# ing920 register map
Vendor: INGChips; Series: ing920xx; File version: 1.0
CPU: CM3 r2p1, little endian, no MPU, no FPU, 2 interrupt priority bits
Registers are 32-bit, read-write, reset 0x0 unless marked. A register's access mark holds for its fields unless they carry their own. Offsets are from the block's base; [hi:lo] are bit positions; {n}, {i} and the like mark numbered series.

## I2C
Base 0x40013000
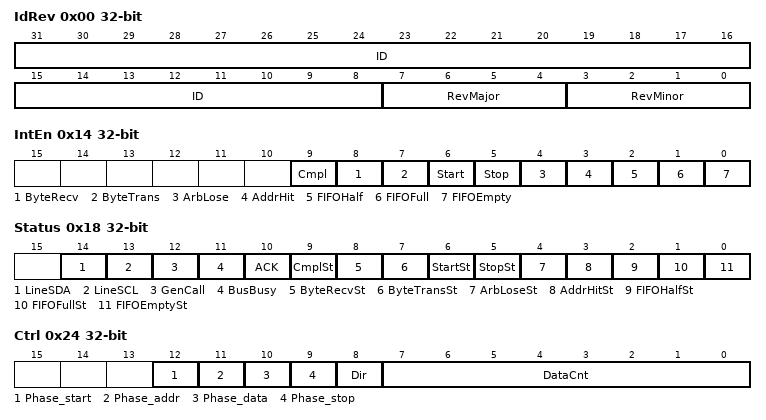
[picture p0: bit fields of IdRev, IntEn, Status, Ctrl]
0x00 IdRev — reg description:
  [31:8] ID — reg description:
  [7:4] RevMajor — reg description:
  [3:0] RevMinor — reg description:
0x10 Cfg — reg description:
  [1:0] FIFOSize
0x14 IntEn — reg description:
  [9] Cmpl — reg description:
  [8] ByteRecv — reg description:
  [7] ByteTrans — reg description:
  [6] Start — reg description:
  [5] Stop — reg description:
  [4] ArbLose — reg description:
  [3] AddrHit — reg description:
  [2] FIFOHalf — reg description:
  [1] FIFOFull — reg description:
  [0] FIFOEmpty — reg description:
0x18 Status — reg description:
  [14] LineSDA — reg description:
  [13] LineSCL — reg description:
  [12] GenCall — reg description:
  [11] BusBusy — reg description:
  [10] ACK — reg description:
  [9] CmplSt — reg description:
  [8] ByteRecvSt — reg description:
  [7] ByteTransSt — reg description:
  [6] StartSt — reg description:
  [5] StopSt — reg description:
  [4] ArbLoseSt — reg description:
  [3] AddrHitSt — reg description:
  [2] FIFOHalfSt — reg description:
  [1] FIFOFullSt — reg description:
  [0] FIFOEmptySt — reg description:
0x1C Addr — reg description:
  [9:0] Addr
0x20 Data — reg description:
  [7:0] Data
0x24 Ctrl — reg description:
  [12] Phase_start — reg description:
  [11] Phase_addr — reg description:
  [10] Phase_data — reg description:
  [9] Phase_stop — reg description:
  [8] Dir — reg description:
  [7:0] DataCnt — reg description:
0x28 Cmd — reg description:
  [2:0] CMD
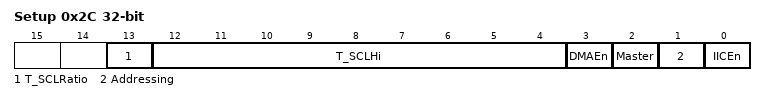
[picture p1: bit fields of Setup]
0x2C Setup — reg description:
  [13] T_SCLRatio — reg description:
  [12:4] T_SCLHi — reg description:
  [3] DMAEn — reg description:
  [2] Master — reg description:
  [1] Addressing — reg description:
  [0] IICEn — reg description:
0x30 TPM — reg description:
  [4:0] TPM

## GPIO0
Base 0x40015000
Same registers: GPIO1 0x40016000
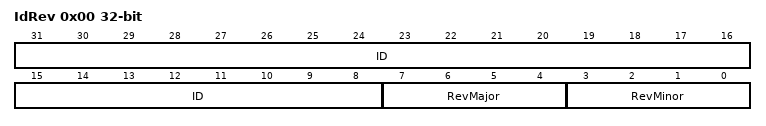
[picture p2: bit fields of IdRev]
0x00 IdRev — reg description:
  [31:8] ID — reg description:
  [7:4] RevMajor — reg description:
  [3:0] RevMinor — reg description:
0x10 Cfg — reg description:
  [5:0] ChannelNum
0x20 DataIn — reg description:
  [20:0] DataIn
0x24 DataOut — reg description:
  [20:0] DataOut
0x28 ChannelDir — reg description:
  [20:0] ChannelDir
0x2C DoutClear — reg description:
  [20:0] DoutClear
0x30 DoutSet — reg description:
  [20:0] DoutSet
0x34 IOIE — reg description:
  [20:0] gpio_ie_reg
0x50 IntrEn — reg description:
  [20:0] IntEn
{0x54+4i} IntrMode{i} (i=0..2) — reg description:
  [2:0] Ch{8i}IntrM
0x64 IntrStatus — reg description:
  [20:0] IntrStatus
0x70 DeBounceEn — reg description:
  [20:0] DeBounceEn
0x74 DeBounceCtrl — reg description:
  [7:0] DBPreScale

## CACHE_CTRL
Base 0x40140000
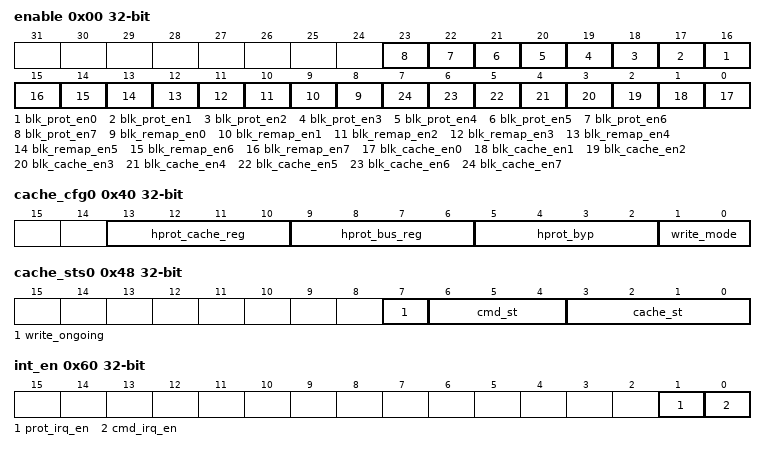
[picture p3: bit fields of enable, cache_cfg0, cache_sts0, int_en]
0x00 enable — reg description:
  [n+16] blk_prot_en{n} (n=0..7) — reg description:
  [n+8] blk_remap_en{n} (n=0..7) — reg description:
  [n] blk_cache_en{n} (n=0..7) — reg description:
{0x0+4i} base_addr{i} (i=1..7) — reg description:
{0x20+4i} remap{i} (i=0..7) — reg description:
0x40 cache_cfg0 — reg description:
  [13:10] hprot_cache_reg — reg description:
  [9:6] hprot_bus_reg — reg description:
  [5:2] hprot_byp — reg description:
  [1:0] write_mode — reg description:
0x44 bus_sts0 — reg description:
  [27:0] prot_detect_addr
0x48 cache_sts0 — reg description:
  [7] write_ongoing — reg description:
  [6:4] cmd_st — reg description:
  [3:0] cache_st — reg description:
0x50 cmd_cfg0 — reg description:
  [27:0] cmd_str_addr
0x54 cmd_cfg1 — reg description:
  [27:0] cmd_end_addr
0x58 cmd_cfg2 — reg description:
  [5:0] cmd_type
0x60 int_en — reg description:
  [1] prot_irq_en — reg description:
  [0] cmd_irq_en — reg description:
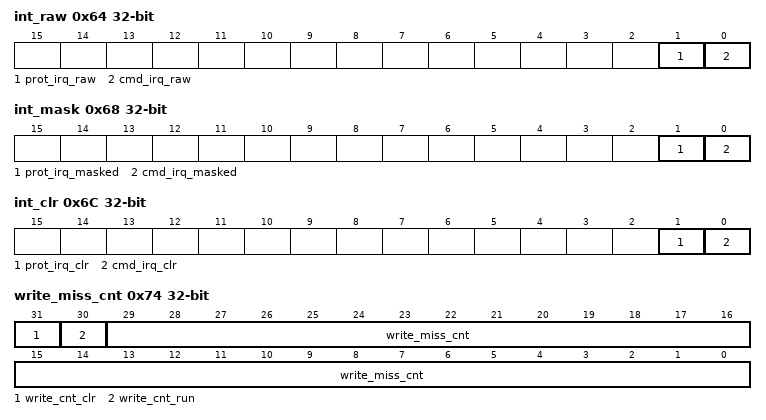
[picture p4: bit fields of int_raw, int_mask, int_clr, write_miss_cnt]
0x64 int_raw — reg description:
  [1] prot_irq_raw — reg description:
  [0] cmd_irq_raw — reg description:
0x68 int_mask — reg description:
  [1] prot_irq_masked — reg description:
  [0] cmd_irq_masked — reg description:
0x6C int_clr — reg description:
  [1] prot_irq_clr — reg description:
  [0] cmd_irq_clr — reg description:
0x70 write_hit_cnt — reg description:
0x74 write_miss_cnt — reg description:
  [31] write_cnt_clr — reg description:
  [30] write_cnt_run — reg description:
  [29:0] write_miss_cnt — reg description:
0x78 read_hit_cnt — reg description:
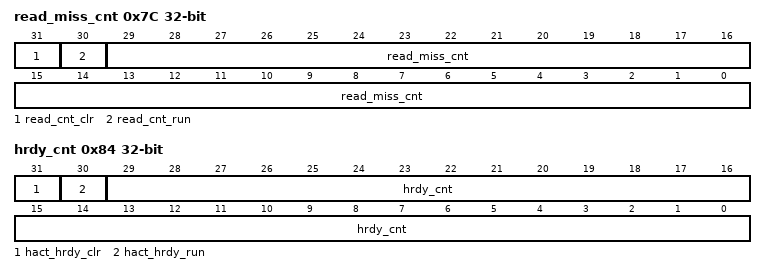
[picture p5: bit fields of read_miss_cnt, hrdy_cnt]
0x7C read_miss_cnt — reg description:
  [31] read_cnt_clr — reg description:
  [30] read_cnt_run — reg description:
  [29:0] read_miss_cnt — reg description:
0x80 hact_cnt — reg description:
0x84 hrdy_cnt — reg description:
  [31] hact_hrdy_clr — reg description:
  [30] hact_hrdy_run — reg description:
  [29:0] hrdy_cnt — reg description:
